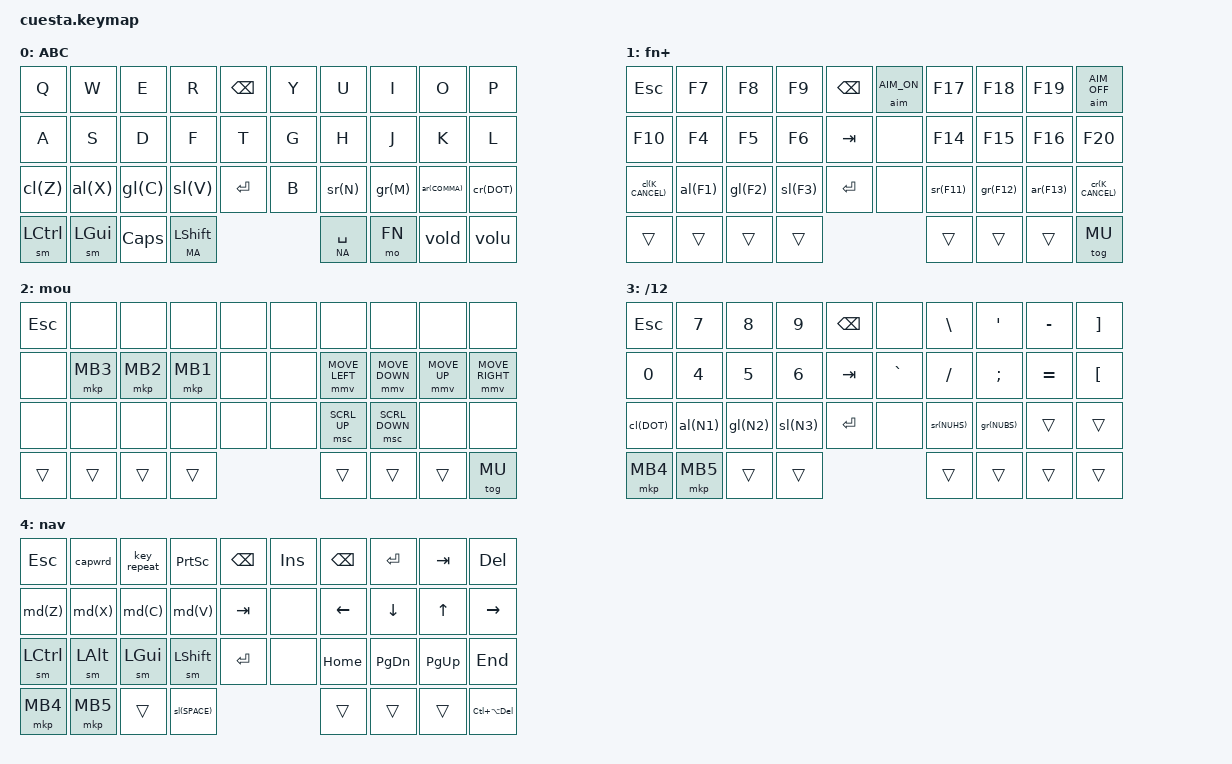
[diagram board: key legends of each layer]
#include <behaviors.dtsi>
#include <dt-bindings/zmk/keys.h>
// #include <dt-bindings/zmk/bt.h>
// #include <behaviors/battery_percentage_printer.dtsi>
#include <behaviors/anti_idle_mode.dtsi>
#include <dt-bindings/anti_idle_mode.h>

&caps_word { continue-list = <MINUS UNDERSCORE BSPC DEL LEFT RIGHT DOT COMMA SEMI SLASH>; };
&sl { release-after-ms = <800>;  /delete-property/ quick-release; };

#define xxxx &none
#define ____ &trans

#define RST &to 0
#define LCKS &kp LC(LA(DEL))

#define FN 1
#define MU 2
#define MA 3
#define NA 4

// Home Row Mods
#define KEYS_L 0 1 2 3 4 10 11 12 13 14 20 21 22 23 24  // Left-hand keys
#define KEYS_R 5 6 7 8 9 15 16 17 18 19 25 26 27 28 29  // Right-hand keys
#define THUMBS 30 31 32 33 34 35 36 37 //38 39          // Thumb keys

#define cl(k) &hml LCTRL k
#define gl(k) &hml LGUI k
#define al(k) &hml LALT k
#define sl(k) &hml LSHFT k

#define cr(k) &hmr RCTRL k
#define gr(k) &hmr RGUI k
#define ar(k) &hmr RALT k
#define sr(k) &hmr RSHFT k

#define md(l) &kkp LG(l) LC(l) 

// Mouse stuff
#define ZMK_MOUSE_DEFAULT_MOVE_VAL 50000  // 600
#define ZMK_MOUSE_DEFAULT_SCRL_VAL 50000  // 10
#include <dt-bindings/zmk/pointing.h>
&mmv {
  acceleration-exponent = <1>;      // 1
  time-to-max-speed-ms = <400>;    // 40
};
&msc {
  acceleration-exponent = <1>;      // 0
  time-to-max-speed-ms = <400>;   // 500
};

/ { 
    macros {
        layshf: lay_shift { compatible = "zmk,behavior-macro-one-param"; wait-ms = <0>; tap-ms = <0>; #binding-cells = <1>;
                            bindings = <&macro_param_1to1>, <&macro_tap &to MACRO_PLACEHOLDER>,  <&macro_press &kp LSHFT>, <&macro_pause_for_release>, <&macro_release &kp LSHFT>, <&macro_tap &to 0>; };
        capwrd: capsword  { compatible = "zmk,behavior-macro"; wait-ms = <0>; tap-ms = <1>; #binding-cells = <0>;
                            bindings = <&macro_tap &kp K_CANCEL &caps_word>; };
        parens: parens    { compatible = "zmk,behavior-macro"; wait-ms = <0>; tap-ms = <1>; #binding-cells = <0>;
                            bindings = <&macro_tap &kp LPAR &kp RPAR &kp LEFT>; };
        rp: reset_kp      { compatible = "zmk,behavior-macro-one-param"; wait-ms = <0>; tap-ms = <0>; #binding-cells = <1>;
                            bindings = <&macro_tap &kp K_CANCEL>, <&macro_param_1to1>, <&macro_tap &kp MACRO_PLACEHOLDER>; };
    };

    behaviors {
        /omit-if-no-ref/ sm: stick_mod       { compatible = "zmk,behavior-sticky-key"; #binding-cells = <1>; bindings = <&kp>; release-after-ms = <2000>; quick-release; lazy; ignore-modifiers; };
        /omit-if-no-ref/ hsk: holdstickymod  { compatible = "zmk,behavior-hold-tap";   #binding-cells = <2>; flavor = "balanced";        tapping-term-ms = <250>; bindings = <&kp>, <&sm>; }; 
        /omit-if-no-ref/ lkp: molayer_kp     { compatible = "zmk,behavior-hold-tap";   #binding-cells = <2>; flavor = "balanced";        tapping-term-ms = <200>; bindings = <&mo>, <&kp>; }; 
        /omit-if-no-ref/ lsm: molayer_sm     { compatible = "zmk,behavior-hold-tap";   #binding-cells = <2>; flavor = "balanced";        tapping-term-ms = <200>; bindings = <&mo>, <&sm>; }; 
        /omit-if-no-ref/ mtg: mo_tog         { compatible = "zmk,behavior-hold-tap";   #binding-cells = <2>; flavor = "hold-preferred";  tapping-term-ms = <300>; bindings = <&mo>, <&tog>; };

        /omit-if-no-ref/ kkp: holdkp_kp      { compatible = "zmk,behavior-hold-tap";   #binding-cells = <2>; flavor = "balanced";        tapping-term-ms = <300>; bindings = <&kp>, <&kp>; }; 
        /omit-if-no-ref/ hml: homerowleft    { compatible = "zmk,behavior-hold-tap";   #binding-cells = <2>; flavor = "balanced";        tapping-term-ms = <280>; 
                                               quick-tap-ms = <175>; require-prior-idle-ms = <180>; bindings = <&kp>, <&kp>; hold-trigger-key-positions = <KEYS_R THUMBS>; hold-trigger-on-release; };
        /omit-if-no-ref/ hmr: homerowright   { compatible = "zmk,behavior-hold-tap";   #binding-cells = <2>; flavor = "balanced";        tapping-term-ms = <280>; 
                                               quick-tap-ms = <175>; require-prior-idle-ms = <180>; bindings = <&kp>, <&kp>; hold-trigger-key-positions = <KEYS_L THUMBS>; hold-trigger-on-release; };

        /omit-if-no-ref/ vold: volum_dw_mute { compatible = "zmk,behavior-mod-morph";  #binding-cells = <0>; bindings = <&kp C_VOL_DN>, <&kp C_MUTE>; mods = <(MOD_LGUI|MOD_RGUI)>; };
        /omit-if-no-ref/ volu: volum_up_mute { compatible = "zmk,behavior-mod-morph";  #binding-cells = <0>; bindings = <&kp C_VOL_UP>, <&kp C_MUTE>; mods = <(MOD_LGUI|MOD_RGUI)>; };
        // /omit-if-no-ref/ blt: bluetoot       { compatible = "zmk,behavior-mod-morph";  #binding-cells = <0>; bindings = <&bt BT_NXT>, <&bt BT_CLR>; mods = <MOD_RALT>; };
    };

    anti_idle {
        compatible = "zmk,anti-idle-generic";
        interval-ms = <60000>; // How often to send actions (ms)
        bindings = <&kp LEFT &kp RIGHT>; // Actions to perform (e.g., mouse move)
        tap_ms = <200>;  // Duration of each action (ms)
        wait_ms = <800>; // Delay between actions (ms)
    };


    keymap {
        compatible = "zmk,keymap";
        abc {
            display-name = "ABC";
            bindings = < 
            //  1           2           3           4           5           6           7           8           9           10
                &kp Q       &kp W       &kp E       &kp R       &kp BSPC    &kp Y       &kp U       &kp I       &kp O       &kp P   
                &kp A       &kp S       &kp D       &kp F       &kp T       &kp G       &kp H       &kp J       &kp K       &kp L   
                cl(Z)       al(X)       gl(C)       sl(V)       &kp ENTER   &kp B       sr(N)       gr(M)       ar(COMMA)   cr(DOT) 
                &sm LCTRL   &sm LGUI    &kp CAPS            &lsm MA LSHFT   &lkp NA SPACE           &mo FN      &vold       &volu    
            >; 
        };

        fun {
            display-name = "fn+";
            bindings = <  
                &kp ESC     &kp F7      &kp F8      &kp F9      &kp BSPC    &aim AIM_ON &kp F17     &kp F18     &kp F19     &aim AIM_OFF 
                &kp F10     &kp F4      &kp F5      &kp F6      &kp TAB     xxxx        &kp F14     &kp F15     &kp F16     &kp F20
                cl(K_CANCEL) al(F1)     gl(F2)      sl(F3)      &kp ENTER   xxxx        sr(F11)     gr(F12)     ar(F13)     cr(K_CANCEL) 
                ____        ____        ____                    ____        ____                    ____        ____        &tog MU
             >; 
        };

        mou {
            display-name = "mou";
            bindings = <  
                &kp ESC     xxxx        xxxx        xxxx        xxxx        xxxx        xxxx        xxxx        xxxx        xxxx 
                xxxx        &mkp MB3    &mkp MB2    &mkp MB1    xxxx        xxxx        &mmv MOVE_LEFT &mmv MOVE_DOWN &mmv MOVE_UP &mmv MOVE_RIGHT  
                xxxx        xxxx        xxxx        xxxx        xxxx        xxxx        &msc SCRL_UP &msc SCRL_DOWN xxxx    xxxx             
                ____        ____        ____                    ____        ____                    ____        ____        &tog MU 
            >; 
        };  

        mat {
            display-name = "/12";
            bindings = <  
                &kp ESC     &kp N7      &kp N8      &kp N9      &kp BSPC    xxxx        &kp BSLH    &kp SQT     &kp MINUS   &kp RBKT   
                &kp N0      &kp N4      &kp N5      &kp N6      &kp TAB     &kp GRAVE   &kp SLASH   &kp SEMI    &kp EQUAL   &kp LBKT
                cl(DOT)     al(N1)      gl(N2)      sl(N3)      &kp ENTER   xxxx        sr(NUHS)    gr(NUBS)    ____        ____       
                &mkp MB4    &mkp MB5    ____                    ____        ____                    ____        ____        ____        
            >; 
        };

        nav {
            display-name = "nav";
            bindings = < 
                &kp ESC     &capwrd     &key_repeat &kp PSCRN   &kp BSPC    &kp INS     &kp BSPC    &kp ENTER   &kp TAB     &kp DEL     
                md(Z)       md(X)       md(C)       md(V)       &kp TAB     xxxx        &kp LEFT    &kp DOWN    &kp UP      &kp RIGHT   
                &sm LCTRL   &sm LALT    &sm LGUI    &sm LSHFT   &kp ENTER   xxxx        &kp HOME    &kp PG_DN   &kp PG_UP   &kp END     
                &mkp MB4    &mkp MB5    ____                    sl(SPACE)   ____                    ____        ____        LCKS
            >; 
        };
        
    }; 
};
